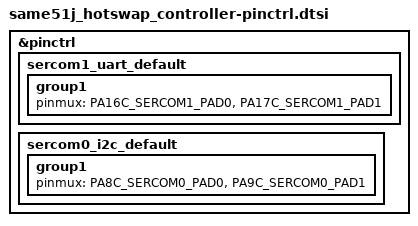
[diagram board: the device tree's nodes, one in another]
#include <dt-bindings/pinctrl/same51g-pinctrl.h>

&pinctrl {
	sercom1_uart_default: sercom1_uart_default {
		group1 {
			pinmux = <PA16C_SERCOM1_PAD0>,
				 <PA17C_SERCOM1_PAD1>;
		};
	};

	sercom0_i2c_default: sercom0_i2c_default {
		group1 {
			pinmux = <PA8C_SERCOM0_PAD0>,
				 <PA9C_SERCOM0_PAD1>;
		};
	};
};
